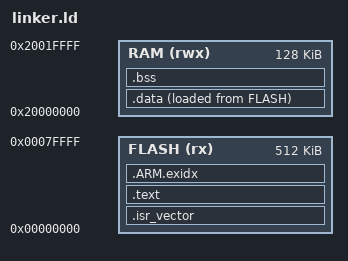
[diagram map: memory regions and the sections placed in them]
ENTRY(Reset_Handler)

MEMORY
{
    FLASH (rx)  : ORIGIN = 0x00000000, LENGTH = 512K
    RAM   (rwx) : ORIGIN = 0x20000000, LENGTH = 128K
}

_stack_top = ORIGIN(RAM) + LENGTH(RAM);

SECTIONS
{
    .isr_vector ORIGIN(FLASH) :
    {
        KEEP(*(.isr_vector))
    } > FLASH

    .text :
    {
        . = ALIGN(4);
        *(.text*)
        *(.rodata*)
        . = ALIGN(4);
    } > FLASH

    .ARM.exidx :
    {
        *(.ARM.exidx*)
    } > FLASH

    .data :
    {
        . = ALIGN(4);
        __data_start = .;
        *(.data*)
        . = ALIGN(4);
        __data_end = .;
    } > RAM AT > FLASH

    __data_load = LOADADDR(.data);

    .bss (NOLOAD) :
    {
        . = ALIGN(4);
        __bss_start = .;
        *(.bss*)
        *(COMMON)
        . = ALIGN(4);
        __bss_end = .;
    } > RAM

    /DISCARD/ :
    {
        *(.comment)
        *(.note*)
    }
}
